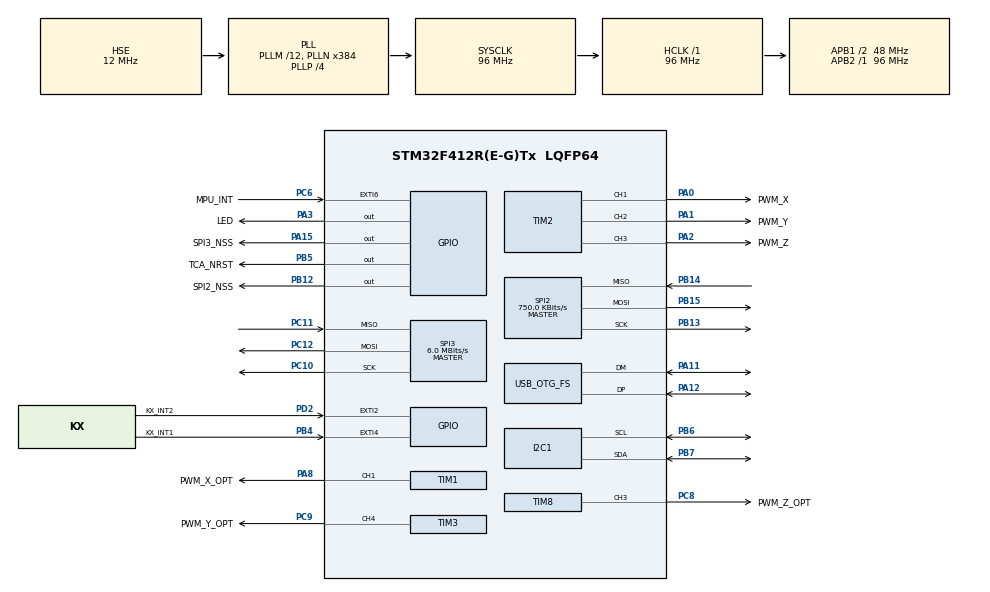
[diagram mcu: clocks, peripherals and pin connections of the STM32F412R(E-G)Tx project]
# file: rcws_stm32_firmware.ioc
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I2C1.I2C_Mode=I2C_Fast
Mcu.Family=STM32F4
Mcu.Name=STM32F412R(E-G)Tx
Mcu.Package=LQFP64
NVIC.EXTI2_IRQn=true\:15\:0\:true\:false\:true\:true\:true\:true
NVIC.EXTI4_IRQn=true\:1\:0\:true\:false\:true\:true\:true\:true
NVIC.EXTI9_5_IRQn=true\:15\:0\:true\:false\:true\:true\:true\:true
NVIC.OTG_FS_IRQn=true\:2\:0\:true\:false\:true\:false\:true\:true
NVIC.PriorityGroup=NVIC_PRIORITYGROUP_4
NVIC.SPI3_IRQn=true\:15\:0\:true\:false\:true\:true\:true\:true
NVIC.TIM6_IRQn=true\:5\:0\:true\:false\:true\:true\:true\:true
NVIC.TIM7_IRQn=true\:0\:0\:false\:false\:true\:true\:true\:true
PA0.GPIO_Label=PWM_X
PA0.Signal=S_TIM2_CH1_ETR
PA1.GPIO_Label=PWM_Y
PA1.Signal=S_TIM2_CH2
PA11.Mode=Device_Only
PA11.Signal=USB_OTG_FS_DM
PA12.Mode=Device_Only
PA12.Signal=USB_OTG_FS_DP
PA13.Mode=Trace_Asynchronous_SW
PA13.Signal=SYS_JTMS-SWDIO
PA14.Mode=Trace_Asynchronous_SW
PA14.Signal=SYS_JTCK-SWCLK
PA15.GPIO_Label=SPI3_NSS
PA15.GPIO_Speed=GPIO_SPEED_FREQ_HIGH
PA15.PinState=GPIO_PIN_SET
PA15.Signal=GPIO_Output
PA2.GPIO_Label=PWM_Z
PA2.Signal=S_TIM2_CH3
PA3.GPIO_Label=LED
PA3.Signal=GPIO_Output
PA8.GPIO_Label=PWM_X_OPT
PA8.Signal=S_TIM1_CH1
PB12.GPIO_Label=SPI2_NSS
PB12.GPIO_Speed=GPIO_SPEED_FREQ_HIGH
PB12.PinState=GPIO_PIN_SET
PB12.Signal=GPIO_Output
PB13.Mode=Full_Duplex_Master
PB13.Signal=SPI2_SCK
PB14.Mode=Full_Duplex_Master
PB14.Signal=SPI2_MISO
PB15.Mode=Full_Duplex_Master
PB15.Signal=SPI2_MOSI
PB3.Mode=Trace_Asynchronous_SW
PB3.Signal=SYS_JTDO-SWO
PB4.GPIO_Label=KX_INT1
PB4.Signal=GPXTI4
PB5.GPIO_Label=TCA_NRST
PB5.GPIO_Speed=GPIO_SPEED_FREQ_MEDIUM
PB5.PinState=GPIO_PIN_SET
PB5.Signal=GPIO_Output
PB6.Mode=I2C
PB6.Signal=I2C1_SCL
PB7.Mode=I2C
PB7.Signal=I2C1_SDA
PC10.Mode=Full_Duplex_Master
PC10.Signal=SPI3_SCK
PC11.Mode=Full_Duplex_Master
PC11.Signal=SPI3_MISO
PC12.Mode=Full_Duplex_Master
PC12.Signal=SPI3_MOSI
PC6.GPIO_Label=MPU_INT
PC6.Signal=GPXTI6
PC8.GPIO_Label=PWM_Z_OPT
PC8.Signal=S_TIM8_CH3
PC9.GPIO_Label=PWM_Y_OPT
PC9.Signal=S_TIM3_CH4
PD2.GPIO_Label=KX_INT2
PD2.Signal=GPXTI2
PH0\ -\ OSC_IN.Mode=HSE-External-Oscillator
PH0\ -\ OSC_IN.Signal=RCC_OSC_IN
PH1\ -\ OSC_OUT.Mode=HSE-External-Oscillator
PH1\ -\ OSC_OUT.Signal=RCC_OSC_OUT
ProjectManager.HeapSize=0x600
ProjectManager.StackSize=0x400
ProjectManager.TargetToolchain=STM32CubeIDE
RCC.AHBFreq_Value=96000000
RCC.APB1CLKDivider=RCC_HCLK_DIV2
RCC.APB1Freq_Value=48000000
RCC.APB1TimFreq_Value=96000000
RCC.APB2Freq_Value=96000000
RCC.APB2TimFreq_Value=96000000
RCC.CortexFreq_Value=96000000
RCC.HCLKFreq_Value=96000000
RCC.HSE_VALUE=12000000
RCC.PLLM=12
RCC.PLLN=384
RCC.PLLP=RCC_PLLP_DIV4
RCC.PLLQ=8
RCC.SYSCLKFreq_VALUE=96000000
RCC.SYSCLKSource=RCC_SYSCLKSOURCE_PLLCLK
RCC.USBFreq_Value=48000000
RCC.VCOOutputFreq_Value=384000000
SH.S_TIM1_CH1.0=TIM1_CH1,PWM Generation1 CH1
SH.S_TIM2_CH1_ETR.0=TIM2_CH1,PWM Generation1 CH1
SH.S_TIM2_CH2.0=TIM2_CH2,PWM Generation2 CH2
SH.S_TIM2_CH3.0=TIM2_CH3,PWM Generation3 CH3
SH.S_TIM3_CH4.0=TIM3_CH4,PWM Generation4 CH4
SH.S_TIM8_CH3.0=TIM8_CH3,PWM Generation3 CH3
SPI2.BaudRatePrescaler=SPI_BAUDRATEPRESCALER_64
SPI2.CLKPhase=SPI_PHASE_2EDGE
SPI2.CLKPolarity=SPI_POLARITY_HIGH
SPI2.CalculateBaudRate=750.0 KBits/s
SPI2.Direction=SPI_DIRECTION_2LINES
SPI2.Mode=SPI_MODE_MASTER
SPI2.TIMode=SPI_TIMODE_DISABLE
SPI2.VirtualType=VM_MASTER
SPI3.BaudRatePrescaler=SPI_BAUDRATEPRESCALER_8
SPI3.CalculateBaudRate=6.0 MBits/s
SPI3.Direction=SPI_DIRECTION_2LINES
SPI3.Mode=SPI_MODE_MASTER
SPI3.VirtualType=VM_MASTER
STMicroelectronics.X-CUBE-ALGOBUILD.1.3.0.LibraryCcDSPOoLibraryJjDSPOoLibrary=true
TIM1.Channel-PWM\ Generation1\ CH1=TIM_CHANNEL_1
TIM2.Channel-PWM\ Generation1\ CH1=TIM_CHANNEL_1
TIM2.Channel-PWM\ Generation2\ CH2=TIM_CHANNEL_2
TIM2.Channel-PWM\ Generation3\ CH3=TIM_CHANNEL_3
TIM3.Channel-PWM\ Generation4\ CH4=TIM_CHANNEL_4
TIM6.Period=1000
TIM6.Prescaler=9600-1
TIM7.Period=1000 - 1
TIM7.Prescaler=96 - 1
TIM8.Channel-PWM\ Generation3\ CH3=TIM_CHANNEL_3
USB_DEVICE.CLASS_NAME_FS=CDC
USB_DEVICE.PID_CDC_FS=48602
USB_DEVICE.PRODUCT_STRING_CDC_FS=rcws_stm32_firmware
USB_DEVICE.USBD_DEBUG_LEVEL=3
USB_DEVICE.VirtualMode=Cdc
USB_DEVICE.VirtualModeFS=Cdc_FS
USB_OTG_FS.VirtualMode=Device_Only
VP_STMicroelectronics.X-CUBE-ALGOBUILD_VS_DSPOoLibraryJjLibrary_1.3.0_1.3.0.Mode=DSPOoLibraryJjLibrary
VP_TIM1_VS_ClockSourceINT.Mode=Internal
VP_TIM2_VS_ClockSourceINT.Mode=Internal
VP_TIM3_VS_ClockSourceINT.Mode=Internal
VP_TIM6_VS_ClockSourceINT.Mode=Enable_Timer
VP_TIM7_VS_ClockSourceINT.Mode=Enable_Timer
VP_TIM8_VS_ClockSourceINT.Mode=Internal
VP_USB_DEVICE_VS_USB_DEVICE_CDC_FS.Mode=CDC_FS
board=custom

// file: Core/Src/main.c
/* USER CODE BEGIN Header */
/**
 ******************************************************************************
 * @file           : main.c
 * @brief          : Main program body
 ******************************************************************************
 * @attention
 *
 * Copyright (c) 2023 STMicroelectronics.
 * All rights reserved.
 *
 * This software is licensed under terms that can be found in the LICENSE file
 * in the root directory of this software component.
 * If no LICENSE file comes with this software, it is provided AS-IS.
 *
 ******************************************************************************
 */
/* USER CODE END Header */
#include "main.h"
#include "usb_device.h"

I2C_HandleTypeDef hi2c1;

SPI_HandleTypeDef hspi2;
SPI_HandleTypeDef hspi3;

TIM_HandleTypeDef htim1;
TIM_HandleTypeDef htim2;
TIM_HandleTypeDef htim3;
TIM_HandleTypeDef htim6;
TIM_HandleTypeDef htim7;
TIM_HandleTypeDef htim8;

void SystemClock_Config(void);
static void MX_GPIO_Init(void);
static void MX_I2C1_Init(void);
static void MX_SPI2_Init(void);
static void MX_SPI3_Init(void);
static void MX_TIM2_Init(void);
static void MX_TIM1_Init(void);
static void MX_TIM3_Init(void);
static void MX_TIM8_Init(void);
static void MX_TIM6_Init(void);
static void MX_TIM7_Init(void);

int main(void)
{

  /* MCU Configuration--------------------------------------------------------*/

  /* Reset of all peripherals, Initializes the Flash interface and the Systick. */
  HAL_Init();

  /* Configure the system clock */
  SystemClock_Config();

  /* Initialize all configured peripherals */
  MX_GPIO_Init();
  MX_I2C1_Init();
  MX_SPI2_Init();
  MX_SPI3_Init();
  MX_TIM2_Init();
  MX_TIM1_Init();
  MX_TIM3_Init();
  MX_TIM8_Init();
  MX_USB_DEVICE_Init();
  MX_TIM6_Init();
  MX_TIM7_Init();
  /* USER CODE BEGIN 2 */

  // LRA project loop enter point
  LRA_Main_EnterPoint();

  /* USER CODE END 2 */

  /* Infinite loop */
  while (1) {

  }
}

void SystemClock_Config(void)
{
  RCC_OscInitTypeDef RCC_OscInitStruct = {0};
  RCC_ClkInitTypeDef RCC_ClkInitStruct = {0};

  /** Configure the main internal regulator output voltage
  */
  __HAL_RCC_PWR_CLK_ENABLE();
  __HAL_PWR_VOLTAGESCALING_CONFIG(PWR_REGULATOR_VOLTAGE_SCALE1);

  /** Initializes the RCC Oscillators according to the specified parameters
  * in the RCC_OscInitTypeDef structure.
  */
  RCC_OscInitStruct.OscillatorType = RCC_OSCILLATORTYPE_HSE;
  RCC_OscInitStruct.HSEState = RCC_HSE_ON;
  RCC_OscInitStruct.PLL.PLLState = RCC_PLL_ON;
  RCC_OscInitStruct.PLL.PLLSource = RCC_PLLSOURCE_HSE;
  RCC_OscInitStruct.PLL.PLLM = 12;
  RCC_OscInitStruct.PLL.PLLN = 384;
  RCC_OscInitStruct.PLL.PLLP = RCC_PLLP_DIV4;
  RCC_OscInitStruct.PLL.PLLQ = 8;
  RCC_OscInitStruct.PLL.PLLR = 2;
  if (HAL_RCC_OscConfig(&RCC_OscInitStruct) != HAL_OK)
  {
    Error_Handler();
  }

  /** Initializes the CPU, AHB and APB buses clocks
  */
  RCC_ClkInitStruct.ClockType = RCC_CLOCKTYPE_HCLK|RCC_CLOCKTYPE_SYSCLK
                              |RCC_CLOCKTYPE_PCLK1|RCC_CLOCKTYPE_PCLK2;
  RCC_ClkInitStruct.SYSCLKSource = RCC_SYSCLKSOURCE_PLLCLK;
  RCC_ClkInitStruct.AHBCLKDivider = RCC_SYSCLK_DIV1;
  RCC_ClkInitStruct.APB1CLKDivider = RCC_HCLK_DIV2;
  RCC_ClkInitStruct.APB2CLKDivider = RCC_HCLK_DIV1;

  if (HAL_RCC_ClockConfig(&RCC_ClkInitStruct, FLASH_LATENCY_3) != HAL_OK)
  {
    Error_Handler();
  }
}

static void MX_I2C1_Init(void)
{

  hi2c1.Instance = I2C1;
  hi2c1.Init.ClockSpeed = 400000;
  hi2c1.Init.DutyCycle = I2C_DUTYCYCLE_2;
  hi2c1.Init.OwnAddress1 = 0;
  hi2c1.Init.AddressingMode = I2C_ADDRESSINGMODE_7BIT;
  hi2c1.Init.DualAddressMode = I2C_DUALADDRESS_DISABLE;
  hi2c1.Init.OwnAddress2 = 0;
  hi2c1.Init.GeneralCallMode = I2C_GENERALCALL_DISABLE;
  hi2c1.Init.NoStretchMode = I2C_NOSTRETCH_DISABLE;
  if (HAL_I2C_Init(&hi2c1) != HAL_OK)
  {
    Error_Handler();
  }

}

static void MX_SPI2_Init(void)
{

  /* SPI2 parameter configuration*/
  hspi2.Instance = SPI2;
  hspi2.Init.Mode = SPI_MODE_MASTER;
  hspi2.Init.Direction = SPI_DIRECTION_2LINES;
  hspi2.Init.DataSize = SPI_DATASIZE_8BIT;
  hspi2.Init.CLKPolarity = SPI_POLARITY_HIGH;
  hspi2.Init.CLKPhase = SPI_PHASE_2EDGE;
  hspi2.Init.NSS = SPI_NSS_SOFT;
  hspi2.Init.BaudRatePrescaler = SPI_BAUDRATEPRESCALER_64;
  hspi2.Init.FirstBit = SPI_FIRSTBIT_MSB;
  hspi2.Init.TIMode = SPI_TIMODE_DISABLE;
  hspi2.Init.CRCCalculation = SPI_CRCCALCULATION_DISABLE;
  hspi2.Init.CRCPolynomial = 10;
  if (HAL_SPI_Init(&hspi2) != HAL_OK)
  {
    Error_Handler();
  }

}

static void MX_SPI3_Init(void)
{

  /* SPI3 parameter configuration*/
  hspi3.Instance = SPI3;
  hspi3.Init.Mode = SPI_MODE_MASTER;
  hspi3.Init.Direction = SPI_DIRECTION_2LINES;
  hspi3.Init.DataSize = SPI_DATASIZE_8BIT;
  hspi3.Init.CLKPolarity = SPI_POLARITY_LOW;
  hspi3.Init.CLKPhase = SPI_PHASE_1EDGE;
  hspi3.Init.NSS = SPI_NSS_SOFT;
  hspi3.Init.BaudRatePrescaler = SPI_BAUDRATEPRESCALER_8;
  hspi3.Init.FirstBit = SPI_FIRSTBIT_MSB;
  hspi3.Init.TIMode = SPI_TIMODE_DISABLE;
  hspi3.Init.CRCCalculation = SPI_CRCCALCULATION_DISABLE;
  hspi3.Init.CRCPolynomial = 10;
  if (HAL_SPI_Init(&hspi3) != HAL_OK)
  {
    Error_Handler();
  }

}

static void MX_TIM1_Init(void)
{

  TIM_ClockConfigTypeDef sClockSourceConfig = {0};
  TIM_MasterConfigTypeDef sMasterConfig = {0};
  TIM_OC_InitTypeDef sConfigOC = {0};
  TIM_BreakDeadTimeConfigTypeDef sBreakDeadTimeConfig = {0};

  htim1.Instance = TIM1;
  htim1.Init.Prescaler = 0;
  htim1.Init.CounterMode = TIM_COUNTERMODE_UP;
  htim1.Init.Period = 65535;
  htim1.Init.ClockDivision = TIM_CLOCKDIVISION_DIV1;
  htim1.Init.RepetitionCounter = 0;
  htim1.Init.AutoReloadPreload = TIM_AUTORELOAD_PRELOAD_DISABLE;
  if (HAL_TIM_Base_Init(&htim1) != HAL_OK)
  {
    Error_Handler();
  }
  sClockSourceConfig.ClockSource = TIM_CLOCKSOURCE_INTERNAL;
  if (HAL_TIM_ConfigClockSource(&htim1, &sClockSourceConfig) != HAL_OK)
  {
    Error_Handler();
  }
  if (HAL_TIM_PWM_Init(&htim1) != HAL_OK)
  {
    Error_Handler();
  }
  sMasterConfig.MasterOutputTrigger = TIM_TRGO_RESET;
  sMasterConfig.MasterSlaveMode = TIM_MASTERSLAVEMODE_DISABLE;
  if (HAL_TIMEx_MasterConfigSynchronization(&htim1, &sMasterConfig) != HAL_OK)
  {
    Error_Handler();
  }
  sConfigOC.OCMode = TIM_OCMODE_PWM1;
  sConfigOC.Pulse = 0;
  sConfigOC.OCPolarity = TIM_OCPOLARITY_HIGH;
  sConfigOC.OCNPolarity = TIM_OCNPOLARITY_HIGH;
  sConfigOC.OCFastMode = TIM_OCFAST_DISABLE;
  sConfigOC.OCIdleState = TIM_OCIDLESTATE_RESET;
  sConfigOC.OCNIdleState = TIM_OCNIDLESTATE_RESET;
  if (HAL_TIM_PWM_ConfigChannel(&htim1, &sConfigOC, TIM_CHANNEL_1) != HAL_OK)
  {
    Error_Handler();
  }
  sBreakDeadTimeConfig.OffStateRunMode = TIM_OSSR_DISABLE;
  sBreakDeadTimeConfig.OffStateIDLEMode = TIM_OSSI_DISABLE;
  sBreakDeadTimeConfig.LockLevel = TIM_LOCKLEVEL_OFF;
  sBreakDeadTimeConfig.DeadTime = 0;
  sBreakDeadTimeConfig.BreakState = TIM_BREAK_DISABLE;
  sBreakDeadTimeConfig.BreakPolarity = TIM_BREAKPOLARITY_HIGH;
  sBreakDeadTimeConfig.AutomaticOutput = TIM_AUTOMATICOUTPUT_DISABLE;
  if (HAL_TIMEx_ConfigBreakDeadTime(&htim1, &sBreakDeadTimeConfig) != HAL_OK)
  {
    Error_Handler();
  }
  HAL_TIM_MspPostInit(&htim1);

}

static void MX_TIM2_Init(void)
{

  TIM_ClockConfigTypeDef sClockSourceConfig = {0};
  TIM_MasterConfigTypeDef sMasterConfig = {0};
  TIM_OC_InitTypeDef sConfigOC = {0};

  htim2.Instance = TIM2;
  htim2.Init.Prescaler = 0;
  htim2.Init.CounterMode = TIM_COUNTERMODE_UP;
  htim2.Init.Period = 4294967295;
  htim2.Init.ClockDivision = TIM_CLOCKDIVISION_DIV1;
  htim2.Init.AutoReloadPreload = TIM_AUTORELOAD_PRELOAD_DISABLE;
  if (HAL_TIM_Base_Init(&htim2) != HAL_OK)
  {
    Error_Handler();
  }
  sClockSourceConfig.ClockSource = TIM_CLOCKSOURCE_INTERNAL;
  if (HAL_TIM_ConfigClockSource(&htim2, &sClockSourceConfig) != HAL_OK)
  {
    Error_Handler();
  }
  if (HAL_TIM_PWM_Init(&htim2) != HAL_OK)
  {
    Error_Handler();
  }
  sMasterConfig.MasterOutputTrigger = TIM_TRGO_RESET;
  sMasterConfig.MasterSlaveMode = TIM_MASTERSLAVEMODE_DISABLE;
  if (HAL_TIMEx_MasterConfigSynchronization(&htim2, &sMasterConfig) != HAL_OK)
  {
    Error_Handler();
  }
  sConfigOC.OCMode = TIM_OCMODE_PWM1;
  sConfigOC.Pulse = 0;
  sConfigOC.OCPolarity = TIM_OCPOLARITY_HIGH;
  sConfigOC.OCFastMode = TIM_OCFAST_DISABLE;
  if (HAL_TIM_PWM_ConfigChannel(&htim2, &sConfigOC, TIM_CHANNEL_1) != HAL_OK)
  {
    Error_Handler();
  }
  if (HAL_TIM_PWM_ConfigChannel(&htim2, &sConfigOC, TIM_CHANNEL_2) != HAL_OK)
  {
    Error_Handler();
  }
  if (HAL_TIM_PWM_ConfigChannel(&htim2, &sConfigOC, TIM_CHANNEL_3) != HAL_OK)
  {
    Error_Handler();
  }
  HAL_TIM_MspPostInit(&htim2);

}

static void MX_TIM3_Init(void)
{

  TIM_ClockConfigTypeDef sClockSourceConfig = {0};
  TIM_MasterConfigTypeDef sMasterConfig = {0};
  TIM_OC_InitTypeDef sConfigOC = {0};

  htim3.Instance = TIM3;
  htim3.Init.Prescaler = 0;
  htim3.Init.CounterMode = TIM_COUNTERMODE_UP;
  htim3.Init.Period = 65535;
  htim3.Init.ClockDivision = TIM_CLOCKDIVISION_DIV1;
  htim3.Init.AutoReloadPreload = TIM_AUTORELOAD_PRELOAD_DISABLE;
  if (HAL_TIM_Base_Init(&htim3) != HAL_OK)
  {
    Error_Handler();
  }
  sClockSourceConfig.ClockSource = TIM_CLOCKSOURCE_INTERNAL;
  if (HAL_TIM_ConfigClockSource(&htim3, &sClockSourceConfig) != HAL_OK)
  {
    Error_Handler();
  }
  if (HAL_TIM_PWM_Init(&htim3) != HAL_OK)
  {
    Error_Handler();
  }
  sMasterConfig.MasterOutputTrigger = TIM_TRGO_RESET;
  sMasterConfig.MasterSlaveMode = TIM_MASTERSLAVEMODE_DISABLE;
  if (HAL_TIMEx_MasterConfigSynchronization(&htim3, &sMasterConfig) != HAL_OK)
  {
    Error_Handler();
  }
  sConfigOC.OCMode = TIM_OCMODE_PWM1;
  sConfigOC.Pulse = 0;
  sConfigOC.OCPolarity = TIM_OCPOLARITY_HIGH;
  sConfigOC.OCFastMode = TIM_OCFAST_DISABLE;
  if (HAL_TIM_PWM_ConfigChannel(&htim3, &sConfigOC, TIM_CHANNEL_4) != HAL_OK)
  {
    Error_Handler();
  }
  HAL_TIM_MspPostInit(&htim3);

}

static void MX_TIM6_Init(void)
{

  TIM_MasterConfigTypeDef sMasterConfig = {0};

  htim6.Instance = TIM6;
  htim6.Init.Prescaler = 9600-1;
  htim6.Init.CounterMode = TIM_COUNTERMODE_UP;
  htim6.Init.Period = 1000;
  htim6.Init.AutoReloadPreload = TIM_AUTORELOAD_PRELOAD_DISABLE;
  if (HAL_TIM_Base_Init(&htim6) != HAL_OK)
  {
    Error_Handler();
  }
  sMasterConfig.MasterOutputTrigger = TIM_TRGO_RESET;
  sMasterConfig.MasterSlaveMode = TIM_MASTERSLAVEMODE_DISABLE;
  if (HAL_TIMEx_MasterConfigSynchronization(&htim6, &sMasterConfig) != HAL_OK)
  {
    Error_Handler();
  }

}

static void MX_TIM7_Init(void)
{

  htim7.Instance = TIM7;
  htim7.Init.Prescaler = 96 - 1;
  htim7.Init.CounterMode = TIM_COUNTERMODE_UP;
  htim7.Init.Period = 1000 - 1;
  htim7.Init.AutoReloadPreload = TIM_AUTORELOAD_PRELOAD_DISABLE;
  if (HAL_TIM_Base_Init(&htim7) != HAL_OK)
  {
    Error_Handler();
  }

}

static void MX_TIM8_Init(void)
{

  TIM_ClockConfigTypeDef sClockSourceConfig = {0};
  TIM_MasterConfigTypeDef sMasterConfig = {0};
  TIM_OC_InitTypeDef sConfigOC = {0};
  TIM_BreakDeadTimeConfigTypeDef sBreakDeadTimeConfig = {0};

  htim8.Instance = TIM8;
  htim8.Init.Prescaler = 0;
  htim8.Init.CounterMode = TIM_COUNTERMODE_UP;
  htim8.Init.Period = 65535;
  htim8.Init.ClockDivision = TIM_CLOCKDIVISION_DIV1;
  htim8.Init.RepetitionCounter = 0;
  htim8.Init.AutoReloadPreload = TIM_AUTORELOAD_PRELOAD_DISABLE;
  if (HAL_TIM_Base_Init(&htim8) != HAL_OK)
  {
    Error_Handler();
  }
  sClockSourceConfig.ClockSource = TIM_CLOCKSOURCE_INTERNAL;
  if (HAL_TIM_ConfigClockSource(&htim8, &sClockSourceConfig) != HAL_OK)
  {
    Error_Handler();
  }
  if (HAL_TIM_PWM_Init(&htim8) != HAL_OK)
  {
    Error_Handler();
  }
  sMasterConfig.MasterOutputTrigger = TIM_TRGO_RESET;
  sMasterConfig.MasterSlaveMode = TIM_MASTERSLAVEMODE_DISABLE;
  if (HAL_TIMEx_MasterConfigSynchronization(&htim8, &sMasterConfig) != HAL_OK)
  {
    Error_Handler();
  }
  sConfigOC.OCMode = TIM_OCMODE_PWM1;
  sConfigOC.Pulse = 0;
  sConfigOC.OCPolarity = TIM_OCPOLARITY_HIGH;
  sConfigOC.OCNPolarity = TIM_OCNPOLARITY_HIGH;
  sConfigOC.OCFastMode = TIM_OCFAST_DISABLE;
  sConfigOC.OCIdleState = TIM_OCIDLESTATE_RESET;
  sConfigOC.OCNIdleState = TIM_OCNIDLESTATE_RESET;
  if (HAL_TIM_PWM_ConfigChannel(&htim8, &sConfigOC, TIM_CHANNEL_3) != HAL_OK)
  {
    Error_Handler();
  }
  sBreakDeadTimeConfig.OffStateRunMode = TIM_OSSR_DISABLE;
  sBreakDeadTimeConfig.OffStateIDLEMode = TIM_OSSI_DISABLE;
  sBreakDeadTimeConfig.LockLevel = TIM_LOCKLEVEL_OFF;
  sBreakDeadTimeConfig.DeadTime = 0;
  sBreakDeadTimeConfig.BreakState = TIM_BREAK_DISABLE;
  sBreakDeadTimeConfig.BreakPolarity = TIM_BREAKPOLARITY_HIGH;
  sBreakDeadTimeConfig.AutomaticOutput = TIM_AUTOMATICOUTPUT_DISABLE;
  if (HAL_TIMEx_ConfigBreakDeadTime(&htim8, &sBreakDeadTimeConfig) != HAL_OK)
  {
    Error_Handler();
  }
  HAL_TIM_MspPostInit(&htim8);

}

static void MX_GPIO_Init(void)
{
  GPIO_InitTypeDef GPIO_InitStruct = {0};

  /* GPIO Ports Clock Enable */
  __HAL_RCC_GPIOH_CLK_ENABLE();
  __HAL_RCC_GPIOA_CLK_ENABLE();
  __HAL_RCC_GPIOB_CLK_ENABLE();
  __HAL_RCC_GPIOC_CLK_ENABLE();
  __HAL_RCC_GPIOD_CLK_ENABLE();

  /*Configure GPIO pin Output Level */
  HAL_GPIO_WritePin(LED_GPIO_Port, LED_Pin, GPIO_PIN_RESET);

  /*Configure GPIO pin Output Level */
  HAL_GPIO_WritePin(GPIOB, SPI2_NSS_Pin|TCA_NRST_Pin, GPIO_PIN_SET);

  /*Configure GPIO pin Output Level */
  HAL_GPIO_WritePin(SPI3_NSS_GPIO_Port, SPI3_NSS_Pin, GPIO_PIN_SET);

  /*Configure GPIO pin : LED_Pin */
  GPIO_InitStruct.Pin = LED_Pin;
  GPIO_InitStruct.Mode = GPIO_MODE_OUTPUT_PP;
  GPIO_InitStruct.Pull = GPIO_NOPULL;
  GPIO_InitStruct.Speed = GPIO_SPEED_FREQ_LOW;
  HAL_GPIO_Init(LED_GPIO_Port, &GPIO_InitStruct);

  /*Configure GPIO pin : SPI2_NSS_Pin */
  GPIO_InitStruct.Pin = SPI2_NSS_Pin;
  GPIO_InitStruct.Mode = GPIO_MODE_OUTPUT_PP;
  GPIO_InitStruct.Pull = GPIO_NOPULL;
  GPIO_InitStruct.Speed = GPIO_SPEED_FREQ_HIGH;
  HAL_GPIO_Init(SPI2_NSS_GPIO_Port, &GPIO_InitStruct);

  /*Configure GPIO pin : MPU_INT_Pin */
  GPIO_InitStruct.Pin = MPU_INT_Pin;
  GPIO_InitStruct.Mode = GPIO_MODE_IT_RISING;
  GPIO_InitStruct.Pull = GPIO_NOPULL;
  HAL_GPIO_Init(MPU_INT_GPIO_Port, &GPIO_InitStruct);

  /*Configure GPIO pin : SPI3_NSS_Pin */
  GPIO_InitStruct.Pin = SPI3_NSS_Pin;
  GPIO_InitStruct.Mode = GPIO_MODE_OUTPUT_PP;
  GPIO_InitStruct.Pull = GPIO_NOPULL;
  GPIO_InitStruct.Speed = GPIO_SPEED_FREQ_HIGH;
  HAL_GPIO_Init(SPI3_NSS_GPIO_Port, &GPIO_InitStruct);

  /*Configure GPIO pin : KX_INT2_Pin */
  GPIO_InitStruct.Pin = KX_INT2_Pin;
  GPIO_InitStruct.Mode = GPIO_MODE_IT_RISING;
  GPIO_InitStruct.Pull = GPIO_NOPULL;
  HAL_GPIO_Init(KX_INT2_GPIO_Port, &GPIO_InitStruct);

  /*Configure GPIO pin : KX_INT1_Pin */
  GPIO_InitStruct.Pin = KX_INT1_Pin;
  GPIO_InitStruct.Mode = GPIO_MODE_IT_RISING;
  GPIO_InitStruct.Pull = GPIO_NOPULL;
  HAL_GPIO_Init(KX_INT1_GPIO_Port, &GPIO_InitStruct);

  /*Configure GPIO pin : TCA_NRST_Pin */
  GPIO_InitStruct.Pin = TCA_NRST_Pin;
  GPIO_InitStruct.Mode = GPIO_MODE_OUTPUT_PP;
  GPIO_InitStruct.Pull = GPIO_NOPULL;
  GPIO_InitStruct.Speed = GPIO_SPEED_FREQ_MEDIUM;
  HAL_GPIO_Init(TCA_NRST_GPIO_Port, &GPIO_InitStruct);

  /* EXTI interrupt init*/
  HAL_NVIC_SetPriority(EXTI2_IRQn, 15, 0);
  HAL_NVIC_EnableIRQ(EXTI2_IRQn);

  HAL_NVIC_SetPriority(EXTI4_IRQn, 1, 0);
  HAL_NVIC_EnableIRQ(EXTI4_IRQn);

  HAL_NVIC_SetPriority(EXTI9_5_IRQn, 15, 0);
  HAL_NVIC_EnableIRQ(EXTI9_5_IRQn);

}

void Error_Handler(void)
{
  __disable_irq();
  while (1) {
  }
}

#ifdef  USE_FULL_ASSERT
/**
  * @brief  Reports the name of the source file and the source line number
  *         where the assert_param error has occurred.
  * @param  file: pointer to the source file name
  * @param  line: assert_param error line source number
  * @retval None
  */
void assert_failed(uint8_t *file, uint32_t line)
{
  /* USER CODE BEGIN 6 */
  /* User can add his own implementation to report the file name and line
     number, ex: printf("Wrong parameters value: file %s on line %d\r\n", file,
     line) */
  /* USER CODE END 6 */
}
#endif /* USE_FULL_ASSERT */
